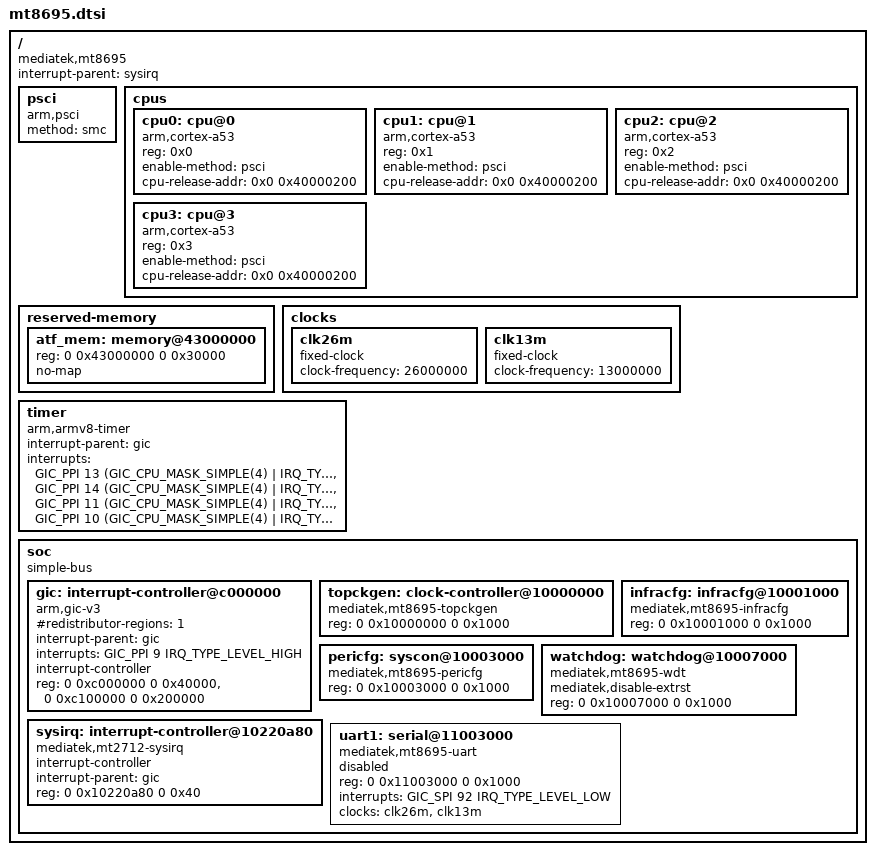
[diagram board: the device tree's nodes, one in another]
// SPDX-License-Identifier: BSD-3-Clause
/*
 * Copyright (c) 2022, David Wronek <w.david0@protonmail.com>
 */

/dts-v1/;


#include <dt-bindings/interrupt-controller/irq.h>
#include <dt-bindings/interrupt-controller/arm-gic.h>


/ {
	compatible = "mediatek,mt8695";
	interrupt-parent = <&sysirq>;
	#address-cells = <2>;
	#size-cells = <2>;

	psci {
		compatible = "arm,psci";
		method = "smc";
	};

	cpus {
		#address-cells = <1>;
		#size-cells = <0>;

		cpu0: cpu@0 {
			device_type = "cpu";
			compatible = "arm,cortex-a53";
			reg = <0x0>;
			enable-method = "psci";
			cpu-release-addr = <0x0 0x40000200>;
		};

		cpu1: cpu@1 {
			device_type = "cpu";
			compatible = "arm,cortex-a53";
			reg = <0x1>;
			enable-method = "psci";
			cpu-release-addr = <0x0 0x40000200>;
		};

		cpu2: cpu@2 {
			device_type = "cpu";
			compatible = "arm,cortex-a53";
			reg = <0x2>;
			enable-method = "psci";
			cpu-release-addr = <0x0 0x40000200>;
		};

		cpu3: cpu@3 {
			device_type = "cpu";
			compatible = "arm,cortex-a53";
			reg = <0x3>;
			enable-method = "psci";
			cpu-release-addr = <0x0 0x40000200>;
		};
	};

	reserved-memory {
		#address-cells = <2>;
		#size-cells = <2>;
		ranges;

		atf_mem: memory@43000000 {
			reg = <0 0x43000000 0 0x30000>;
			no-map;
		};
	};

	clocks {
		clk26m: clk26m {
			compatible = "fixed-clock";
			clock-frequency = <26000000>;
			#clock-cells = <0>;
		};

		clk13m: clk13m {
			compatible = "fixed-clock";
			clock-frequency = <13000000>;
			#clock-cells = <0>;
		};
	};

	timer {
		compatible = "arm,armv8-timer";
		interrupt-parent = <&gic>;
		interrupts = <GIC_PPI 13
			     (GIC_CPU_MASK_SIMPLE(4) | IRQ_TYPE_LEVEL_LOW)>,
			     <GIC_PPI 14
			     (GIC_CPU_MASK_SIMPLE(4) | IRQ_TYPE_LEVEL_LOW)>,
			     <GIC_PPI 11
			     (GIC_CPU_MASK_SIMPLE(4) | IRQ_TYPE_LEVEL_LOW)>,
			     <GIC_PPI 10
			     (GIC_CPU_MASK_SIMPLE(4) | IRQ_TYPE_LEVEL_LOW)>;
	};

	soc {
		#address-cells = <2>;
		#size-cells = <2>;
		compatible = "simple-bus";
		ranges;

		gic: interrupt-controller@c000000 {
			compatible = "arm,gic-v3";
			#interrupt-cells = <3>;
			#redistributor-regions = <1>;
			interrupt-parent = <&gic>;
			interrupts = <GIC_PPI 9 IRQ_TYPE_LEVEL_HIGH>;
			interrupt-controller;
			reg = <0 0xc000000 0 0x40000>,	/* GICD */
				  <0 0xc100000 0 0x200000>;	/* GICR */
		};

		topckgen: clock-controller@10000000 {
			compatible = "mediatek,mt8695-topckgen";
			reg = <0 0x10000000 0 0x1000>;
			#clock-cells = <1>;
		};

		infracfg: infracfg@10001000 {
			compatible = "mediatek,mt8695-infracfg", "syscon";
			reg = <0 0x10001000 0 0x1000>;
			#clock-cells = <1>;
			#reset-cells = <1>;
		};

		pericfg: syscon@10003000 {
			compatible = "mediatek,mt8695-pericfg", "syscon";
			reg = <0 0x10003000 0 0x1000>;
			#clock-cells = <1>;
		};

		watchdog: watchdog@10007000 {
			compatible = "mediatek,mt8695-wdt",
						"mediatek,mt6589-wdt";
			mediatek,disable-extrst;
			reg = <0 0x10007000 0 0x1000>;
			#reset-cells = <1>;
		};

		sysirq: interrupt-controller@10220a80 {
			compatible = "mediatek,mt2712-sysirq",
					 "mediatek,mt6577-sysirq";
			interrupt-controller;
			#interrupt-cells = <3>;
			interrupt-parent = <&gic>;
			reg = <0 0x10220a80 0 0x40>;
		};

		uart1: serial@11003000 {
			compatible = "mediatek,mt8695-uart", "mediatek,mt6577-uart";
			reg = <0 0x11003000 0 0x1000>;
			interrupts = <GIC_SPI 92 IRQ_TYPE_LEVEL_LOW>;
			clocks = <&clk26m>, <&clk13m>;
			clock-names = "baud", "bus";

			status = "disabled";
		};
	};
};
